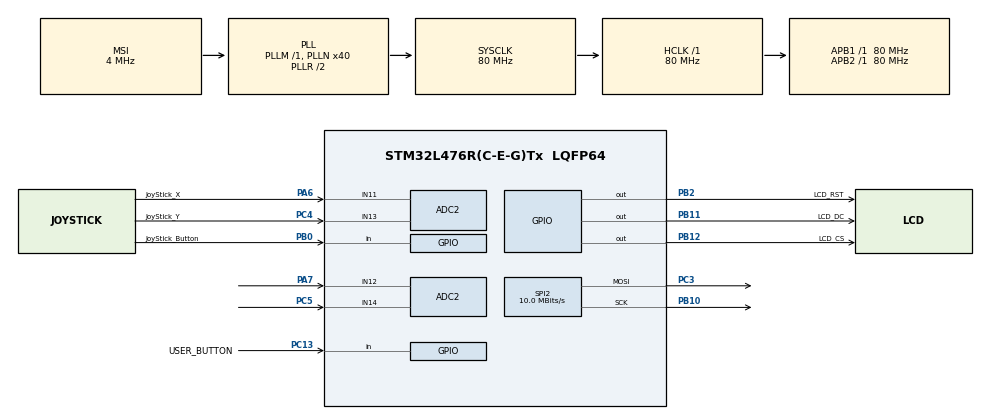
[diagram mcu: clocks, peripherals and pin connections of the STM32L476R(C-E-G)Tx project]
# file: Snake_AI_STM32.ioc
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ADC2.Channel-2\#ChannelRegularConversion=ADC_CHANNEL_11
ADC2.NbrOfConversionFlag=1
ADC2.OffsetNumber-2\#ChannelRegularConversion=ADC_OFFSET_NONE
ADC2.Rank-2\#ChannelRegularConversion=1
ADC2.SamplingTime-2\#ChannelRegularConversion=ADC_SAMPLETIME_2CYCLES_5
ADC2.SingleDiff-2\#ChannelRegularConversion=ADC_DIFFERENTIAL_ENDED
Mcu.Family=STM32L4
Mcu.Name=STM32L476R(C-E-G)Tx
Mcu.Package=LQFP64
NVIC.PriorityGroup=NVIC_PRIORITYGROUP_4
PA6.GPIO_Label=JoyStick_X
PA6.Signal=ADCx_IN11
PA7.Signal=ADCx_IN12
PB0.GPIO_Label=JoyStick_Button
PB0.Signal=GPIO_Input
PB10.Mode=TX_Only_Simplex_Unidirect_Master
PB10.Signal=SPI2_SCK
PB11.GPIO_Label=LCD_DC
PB11.Signal=GPIO_Output
PB12.GPIO_Label=LCD_CS
PB12.Signal=GPIO_Output
PB2.GPIO_Label=LCD_RST
PB2.Signal=GPIO_Output
PC13.GPIO_Label=USER_BUTTON
PC13.Signal=GPIO_Input
PC3.Mode=TX_Only_Simplex_Unidirect_Master
PC3.Signal=SPI2_MOSI
PC4.GPIO_Label=JoyStick_Y
PC4.Signal=ADCx_IN13
PC5.Signal=ADCx_IN14
ProjectManager.HeapSize=0x800
ProjectManager.StackSize=0x800
ProjectManager.TargetToolchain=STM32CubeIDE
RCC.ADCFreq_Value=32000000
RCC.AHBFreq_Value=80000000
RCC.APB1Freq_Value=80000000
RCC.APB1TimFreq_Value=80000000
RCC.APB2Freq_Value=80000000
RCC.APB2TimFreq_Value=80000000
RCC.CortexFreq_Value=80000000
RCC.HCLKFreq_Value=80000000
RCC.HSE_VALUE=8000000
RCC.HSI_VALUE=16000000
RCC.LSE_VALUE=32768
RCC.MSI_VALUE=4000000
RCC.PLLN=40
RCC.PLLSAI1N=16
RCC.SYSCLKFreq_VALUE=80000000
RCC.SYSCLKSource=RCC_SYSCLKSOURCE_PLLCLK
RCC.USBFreq_Value=32000000
RCC.VCOOutputFreq_Value=160000000
SH.ADCx_IN11.0=ADC2_IN11,IN11-Differential
SH.ADCx_IN12.0=ADC2_IN12,IN11-Differential
SH.ADCx_IN13.0=ADC2_IN13,IN13-Differential
SH.ADCx_IN14.0=ADC2_IN14,IN13-Differential
SPI2.BaudRatePrescaler=SPI_BAUDRATEPRESCALER_8
SPI2.CLKPolarity=SPI_POLARITY_LOW
SPI2.CalculateBaudRate=10.0 MBits/s
SPI2.DataSize=SPI_DATASIZE_8BIT
SPI2.Direction=SPI_DIRECTION_2LINES
SPI2.Mode=SPI_MODE_MASTER
SPI2.VirtualType=VM_MASTER
STMicroelectronics.X-CUBE-AI.10.1.0.ActivationBufferSizeList=2384
STMicroelectronics.X-CUBE-AI.10.1.0.ActivationBuffers=pool0
STMicroelectronics.X-CUBE-AI.10.1.0.ActivationNames=pool0
STMicroelectronics.X-CUBE-AI.10.1.0.ActivationSizes=AI_MYAI_DATA_ACTIVATION_1_SIZE
STMicroelectronics.X-CUBE-AI.10.1.0.ApplicationCcDeviceJjApplication=ApplicationTemplate
STMicroelectronics.X-CUBE-AI.10.1.0.HeapSize=0x800
STMicroelectronics.X-CUBE-AI.10.1.0.InternalRamActivationBufferMaxSize=AI_MYAI_DATA_ACTIVATIONS_SIZE
STMicroelectronics.X-CUBE-AI.10.1.0.LatestDirectoryUsed-49a9f73c79c940e9320656cd775a5b980b8a1153d52cb95478d9393e2f4c3cbf=C\:\\Users\\barte\\STM32CubeIDE\\workspace_1.16.0\\TFT_LCD_First
STMicroelectronics.X-CUBE-AI.10.1.0.MaximumNumberOfInputLayer=1
STMicroelectronics.X-CUBE-AI.10.1.0.MaximumNumberOfOutputLayer=1
STMicroelectronics.X-CUBE-AI.10.1.0.MaximumSizeOfInputLayer=1
STMicroelectronics.X-CUBE-AI.10.1.0.MaximumSizeOfOutputLayer=1
STMicroelectronics.X-CUBE-AI.10.1.0.ModelActualCompression-49a9f73c79c940e9320656cd775a5b980b8a1153d52cb95478d9393e2f4c3cbf=0.0
STMicroelectronics.X-CUBE-AI.10.1.0.ModelCompression-49a9f73c79c940e9320656cd775a5b980b8a1153d52cb95478d9393e2f4c3cbf=None
STMicroelectronics.X-CUBE-AI.10.1.0.ModelFlashOccupation-49a9f73c79c940e9320656cd775a5b980b8a1153d52cb95478d9393e2f4c3cbf=23558
STMicroelectronics.X-CUBE-AI.10.1.0.ModelHashList=49a9f73c79c940e9320656cd775a5b980b8a1153d52cb95478d9393e2f4c3cbf
STMicroelectronics.X-CUBE-AI.10.1.0.ModelKind-49a9f73c79c940e9320656cd775a5b980b8a1153d52cb95478d9393e2f4c3cbf=ONNX
STMicroelectronics.X-CUBE-AI.10.1.0.ModelMacc-49a9f73c79c940e9320656cd775a5b980b8a1153d52cb95478d9393e2f4c3cbf=4099
STMicroelectronics.X-CUBE-AI.10.1.0.ModelName-49a9f73c79c940e9320656cd775a5b980b8a1153d52cb95478d9393e2f4c3cbf=myai
STMicroelectronics.X-CUBE-AI.10.1.0.ModelNameList=myai
STMicroelectronics.X-CUBE-AI.10.1.0.ModelRamOccupation-49a9f73c79c940e9320656cd775a5b980b8a1153d52cb95478d9393e2f4c3cbf=2384
STMicroelectronics.X-CUBE-AI.10.1.0.ModelStructureFile-49a9f73c79c940e9320656cd775a5b980b8a1153d52cb95478d9393e2f4c3cbf=model_best.onnx
STMicroelectronics.X-CUBE-AI.10.1.0.ModelType-49a9f73c79c940e9320656cd775a5b980b8a1153d52cb95478d9393e2f4c3cbf=STM32Cube.AI MCU runtime
STMicroelectronics.X-CUBE-AI.10.1.0.ReadyForCodeGeneration=true
STMicroelectronics.X-CUBE-AI.10.1.0.StackSize=0x800
STMicroelectronics.X-CUBE-AI.10.1.0.WorkingBufferStartAddrList=0xFFFFFFFF
STMicroelectronics.X-CUBE-AI.10.1.0.XAaCUBEAaAICcArtificialOoIntelligenceJjCore=true
STMicroelectronics.X-CUBE-AI.10.1.0.copyWeightToRam=false
STMicroelectronics.X-CUBE-AI.10.1.0.customLayerConfigEnabled=false
STMicroelectronics.X-CUBE-AI.10.1.0.noOnnxIoTranspose=false
STMicroelectronics.X-CUBE-AI.10.1.0.useInputAllocation=true
STMicroelectronics.X-CUBE-AI.10.1.0.useOutputAllocation=true
VP_CRC_VS_CRC.Mode=CRC_Activate
VP_STMicroelectronics.X-CUBE-AI_VS_ArtificialOoIntelligenceJjXAaCUBEAaAI_10.1.0.Mode=ArtificialOoIntelligenceJjXAaCUBEAaAI
VP_STMicroelectronics.X-CUBE-AI_VS_DeviceJjApplication_10.1.0.Mode=DeviceJjApplication
board=custom

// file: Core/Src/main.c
/* USER CODE BEGIN Header */
/**
  ******************************************************************************
  * @file           : main.c
  * @brief          : Main program body
  ******************************************************************************
  * @attention
  *
  * Copyright (c) 2024 STMicroelectronics.
  * All rights reserved.
  *
  * This software is licensed under terms that can be found in the LICENSE file
  * in the root directory of this software component.
  * If no LICENSE file comes with this software, it is provided AS-IS.
  *
  ******************************************************************************
  */
/* USER CODE END Header */
#include "main.h"
#include "adc.h"
#include "crc.h"
#include "spi.h"
#include "gpio.h"
#include "app_x-cube-ai.h"

/* USER CODE BEGIN Includes */

#include "lcd.h"
#include "forbot_logo.c"
#include "Button_Lib.h"
#include "myai.h"
#include "myai_data.h"
#include "myai_data_params.h"
#include "Snake_Game.h"

counter = 0;

/* USER CODE END Includes */

void SystemClock_Config(void);

int main(void)
{

  /* MCU Configuration--------------------------------------------------------*/

  /* Reset of all peripherals, Initializes the Flash interface and the Systick. */
  HAL_Init();

  /* Configure the system clock */
  SystemClock_Config();

  /* Initialize all configured peripherals */
  MX_GPIO_Init();
  MX_SPI2_Init();
  MX_ADC2_Init();
  MX_CRC_Init();
  MX_X_CUBE_AI_Init();
  /* USER CODE BEGIN 2 */

  lcd_init();
  lcd_clear_screen(0x0000);     // czarne tło
  lcd_copy();
  HAL_Delay(1000);

/*  int state[STATE_SIZE] = {1, 0, 1, 0, 0, 1, 0, 0, 0, 0, 1};
  float output[3];

  runAI(state, output);

  // Znajdź indeks największego wyniku z AI
  int best_action = 0;
  for (int i = 1; i < 3; i++) {
      if (output[i] > output[best_action]) {
          best_action = i;
      }
  }

  // Wybierz kolor w zależności od akcji
  uint16_t line_color;
  switch (best_action) {
      case 0:
          line_color = 0xF800; // czerwony
          break;
      case 1:
          line_color = 0x07E0; // zielony
          break;
      case 2:
          line_color = 0x001F; // niebieski
          break;
      default:
          line_color = 0xFFFF; // biały jako domyślny
          break;
  }

  // Narysuj przekątną
  int max = (LCD_WIDTH < LCD_HEIGHT) ? LCD_WIDTH : LCD_HEIGHT;
  for (int i = 0; i < max; i++) {
      lcd_put_pixel(i, i, line_color);
  }

  // Wyślij bufor na ekran
  lcd_copy();*/
  /* USER CODE END 2 */

  /* Infinite loop */
  /* USER CODE BEGIN WHILE */

  /* Infinite loop */
  /* USER CODE BEGIN WHILE */

  while (1)
  {

	  /*Button_Status statusOfButton_1 = Status_Button(USER_BUTTON_GPIO_Port, USER_BUTTON_Pin);

	  switch (statusOfButton_1)
	  {

	  case Ready2GO : lcd_copy() ; break ;

	  case Press: lcd_draw_image(32, 0, 100, 80,forbot_logo); counter=1;   ;break;

	  case Hold : lcd_draw_image(0, 32, 100, 80,forbot_logo) ;
			  if(counter !=0)

	  {
				  lcd_copy();
				  counter=0;
	  }
	  break;

	  default : break;

	  }*/
	  playGame();

    /* USER CODE END WHILE */

  MX_X_CUBE_AI_Process();
  }
}

void SystemClock_Config(void)
{
  RCC_OscInitTypeDef RCC_OscInitStruct = {0};
  RCC_ClkInitTypeDef RCC_ClkInitStruct = {0};

  /** Configure the main internal regulator output voltage
  */
  if (HAL_PWREx_ControlVoltageScaling(PWR_REGULATOR_VOLTAGE_SCALE1) != HAL_OK)
  {
    Error_Handler();
  }

  /** Initializes the RCC Oscillators according to the specified parameters
  * in the RCC_OscInitTypeDef structure.
  */
  RCC_OscInitStruct.OscillatorType = RCC_OSCILLATORTYPE_MSI;
  RCC_OscInitStruct.MSIState = RCC_MSI_ON;
  RCC_OscInitStruct.MSICalibrationValue = 0;
  RCC_OscInitStruct.MSIClockRange = RCC_MSIRANGE_6;
  RCC_OscInitStruct.PLL.PLLState = RCC_PLL_ON;
  RCC_OscInitStruct.PLL.PLLSource = RCC_PLLSOURCE_MSI;
  RCC_OscInitStruct.PLL.PLLM = 1;
  RCC_OscInitStruct.PLL.PLLN = 40;
  RCC_OscInitStruct.PLL.PLLP = RCC_PLLP_DIV7;
  RCC_OscInitStruct.PLL.PLLQ = RCC_PLLQ_DIV2;
  RCC_OscInitStruct.PLL.PLLR = RCC_PLLR_DIV2;
  if (HAL_RCC_OscConfig(&RCC_OscInitStruct) != HAL_OK)
  {
    Error_Handler();
  }

  /** Initializes the CPU, AHB and APB buses clocks
  */
  RCC_ClkInitStruct.ClockType = RCC_CLOCKTYPE_HCLK|RCC_CLOCKTYPE_SYSCLK
                              |RCC_CLOCKTYPE_PCLK1|RCC_CLOCKTYPE_PCLK2;
  RCC_ClkInitStruct.SYSCLKSource = RCC_SYSCLKSOURCE_PLLCLK;
  RCC_ClkInitStruct.AHBCLKDivider = RCC_SYSCLK_DIV1;
  RCC_ClkInitStruct.APB1CLKDivider = RCC_HCLK_DIV1;
  RCC_ClkInitStruct.APB2CLKDivider = RCC_HCLK_DIV1;

  if (HAL_RCC_ClockConfig(&RCC_ClkInitStruct, FLASH_LATENCY_4) != HAL_OK)
  {
    Error_Handler();
  }
}

void Error_Handler(void)
{
  __disable_irq();
  while (1)
  {
  }
}
